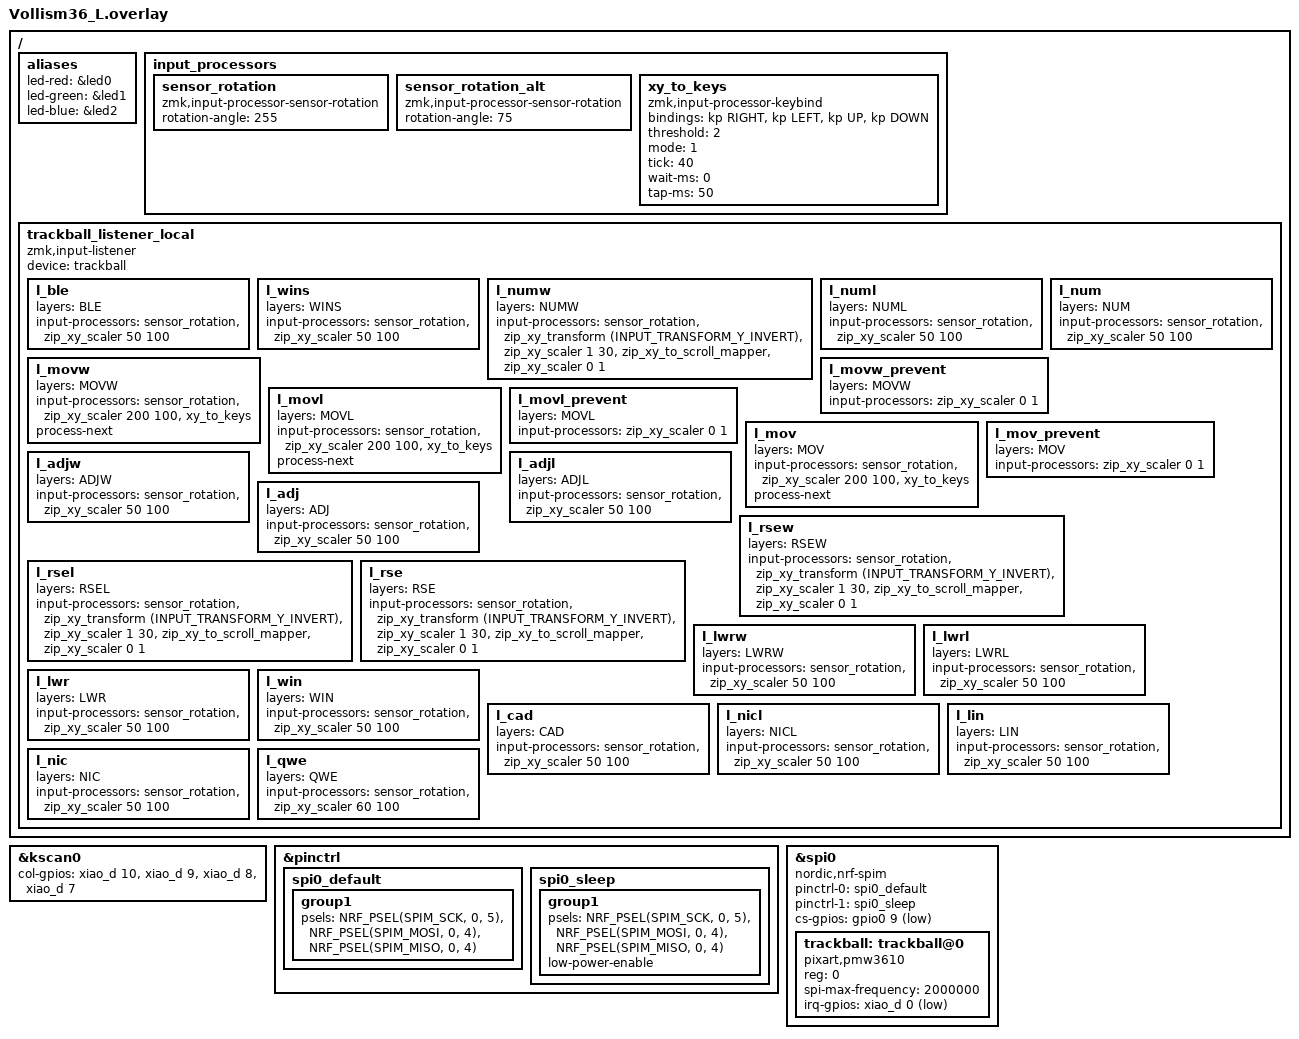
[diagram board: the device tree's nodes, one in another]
#include "Vollism36.dtsi"
#include <input/processors.dtsi>
#include <dt-bindings/zmk/input_transform.h>
#include <dt-bindings/zmk/keys.h>
#include <dt-bindings/input/input-event-codes.h>
#include <input/processors/sensor_rotation.dtsi>
#include <input/processors/zmk-input-processor-keybind.dtsi>
// #include <zephyr/dt-bindings/input/input-event-codes.h>
// #include <behaviors/naginata.dtsi>

#define QWE 0
#define NIC 1
#define LIN 2
#define NICL 3
#define CAD 4
#define WIN 5
#define LWR 6
#define LWRL 7
#define LWRW 8
#define RSE 9
#define RSEL 10
#define RSEW 11
#define ADJ 12
#define ADJL 13
#define ADJW 14
#define MOV 15
#define MOVL 16
#define MOVW 17
#define NUM 18
#define NUML 19
#define NUMW 20
#define WINS 21
#define BLE 22

/ {
    /* 既存の定義（input_processorsなど）と同じ階層に追加 */
    aliases {
        led-red = &led0;   /* Xiao BLE の赤色LEDラベル */
        led-green = &led1; /* Xiao BLE の緑色LEDラベル */
        led-blue = &led2;  /* Xiao BLE の青色LEDラベル */
    };
};


&kscan0 {
        col-gpios
            = <&xiao_d 10 GPIO_ACTIVE_HIGH>
            , <&xiao_d 9 GPIO_ACTIVE_HIGH> 
            , <&xiao_d 8 GPIO_ACTIVE_HIGH> 
            , <&xiao_d 7 GPIO_ACTIVE_HIGH>
            ;
};

/ {
    input_processors {
        /* 既存のデフォルト角度（255度） */
        sensor_rotation: sensor_rotation {
            compatible = "zmk,input-processor-sensor-rotation";
            #input-processor-cells = <0>;
            rotation-angle = <255>;
        };
        /* 新設：別のレイヤで使いたい角度（例：75度） */
        sensor_rotation_alt: sensor_rotation_alt {
            compatible = "zmk,input-processor-sensor-rotation";
            #input-processor-cells = <0>;
            rotation-angle = <75>;  /* ここに対象レイヤで使いたい角度を指定 */
        };

        xy_to_keys: xy_to_keys {
            compatible = "zmk,input-processor-keybind";
            #input-processor-cells = <0>;
            bindings = <&kp RIGHT>, <&kp LEFT>, <&kp UP>, <&kp DOWN>;
            threshold = <2>; // 方向キーが勝手に入る場合はしきい値を少し上げる
            mode = <1>;
            tick = <40>; // ティック間隔
			wait-ms = <0>; // 待機時間
			tap-ms = <50>; // タップ時間
        };
    };

    trackball_listener_local {
        compatible = "zmk,input-listener";
        device = <&trackball>;

        /* ==========================================================
        Layer 22: BLE (通常マウス)
        ========================================================== */
        l_ble {
            layers = <BLE>;
            input-processors = <&sensor_rotation>
                            , <&zip_xy_scaler 50 100>; // スケーリング（50/100）
        };

        /* ==========================================================
        Layer 21: WINS (通常マウス)
        ========================================================== */
        l_wins {
            layers = <WINS>;
            input-processors = <&sensor_rotation>
                            , <&zip_xy_scaler 50 100>; // スケーリング（50/100）
        };

        /* ==========================================================
        Layer 20: NUMW (スクロール)
        ========================================================== */
         l_numw {
            layers = <NUMW>;
            input-processors = 
                <&sensor_rotation>,
                <&zip_xy_transform (INPUT_TRANSFORM_Y_INVERT)>,
                <&zip_xy_scaler 1 30>,
                <&zip_xy_to_scroll_mapper>,
                <&zip_xy_scaler 0 1>; 
        };

        /* ==========================================================
        Layer 19: NUML (通常マウス)
        ========================================================== */
        l_numl {
            layers = <NUML>;
            input-processors = <&sensor_rotation>
                            , <&zip_xy_scaler 50 100>; // スケーリング（50/100）
        };

        /* ==========================================================
        Layer 18: NUM (通常マウス)
        ========================================================== */
        l_num {
            layers = <NUM>;
            input-processors = <&sensor_rotation>
                            , <&zip_xy_scaler 50 100>; // スケーリング（50/100）
        };

        /* ==========================================================
        Layer 17: MOVW (方向キー変換)
        ========================================================== */
        l_movw {
            layers = <MOVW>; 
            input-processors = 
                <&sensor_rotation>, 
                <&zip_xy_scaler 200 100>, 
                <&xy_to_keys>;
            process-next;
        };

        l_movw_prevent {
            layers = <MOVW>;
            input-processors = <&zip_xy_scaler 0 1>;
        };

        /* ==========================================================
        Layer 16: MOVL (方向キー変換)
        ========================================================== */
        l_movl {
            layers = <MOVL>; 
            input-processors = 
                <&sensor_rotation>, 
                <&zip_xy_scaler 200 100>, 
                <&xy_to_keys>;
            process-next;
        };

        l_movl_prevent {
            layers = <MOVL>;
            input-processors = <&zip_xy_scaler 0 1>;
        };

        /* ==========================================================
        Layer 15: MOV (方向キー変換)
        ========================================================== */
        l_mov {
            layers = <MOV>; 
            input-processors = 
                <&sensor_rotation>, 
                <&zip_xy_scaler 200 100>, 
                <&xy_to_keys>;
            process-next;
        };

        l_mov_prevent {
            layers = <MOV>;
            input-processors = <&zip_xy_scaler 0 1>;
        };

        /* ==========================================================
        Layer 14: ADJW (通常マウス)
        ========================================================== */
        l_adjw {
            layers = <ADJW>;
            input-processors = <&sensor_rotation>
                            , <&zip_xy_scaler 50 100>; // スケーリング（50/100）
        };

        /* ==========================================================
        Layer 13: ADJL (通常マウス)
        ========================================================== */
        l_adjl {
            layers = <ADJL>;
            input-processors = <&sensor_rotation>
                            , <&zip_xy_scaler 50 100>; // スケーリング（50/100）
        };

        /* ==========================================================
        Layer 12: ADJ (通常マウス)
        ========================================================== */
        l_adj {
            layers = <ADJ>;
            input-processors = <&sensor_rotation>
                            , <&zip_xy_scaler 50 100>; // スケーリング（50/100）
        };

        /* ==========================================================
        Layer 11: RSEW (スクロール)
        ========================================================== */
        l_rsew {
            layers = <RSEW>;
            input-processors = 
                <&sensor_rotation>,
                <&zip_xy_transform (INPUT_TRANSFORM_Y_INVERT)>,
                <&zip_xy_scaler 1 30>,
                <&zip_xy_to_scroll_mapper>,
                <&zip_xy_scaler 0 1>; 
        };

        /* ==========================================================
        Layer 10: RSEL (スクロール)
        ========================================================== */
        l_rsel {
            layers = <RSEL>;
            input-processors = 
                <&sensor_rotation>,
                <&zip_xy_transform (INPUT_TRANSFORM_Y_INVERT)>,
                <&zip_xy_scaler 1 30>,
                <&zip_xy_to_scroll_mapper>,
                <&zip_xy_scaler 0 1>; 
        };

        /* ==========================================================
        Layer 9: RSE (スクロール)
        ========================================================== */
        l_rse {
            layers = <RSE>;
            input-processors = 
                <&sensor_rotation>,
                <&zip_xy_transform (INPUT_TRANSFORM_Y_INVERT)>,
                <&zip_xy_scaler 1 30>,
                <&zip_xy_to_scroll_mapper>,
                <&zip_xy_scaler 0 1>; 
        };

        /* ==========================================================
        Layer 8: LWRW (通常マウス)
        ========================================================== */
        l_lwrw {
            layers = <LWRW>;
            input-processors = <&sensor_rotation>
                            , <&zip_xy_scaler 50 100>; // スケーリング（50/100）
        };

        /* ==========================================================
        Layer 7: LWRL (通常マウス)
        ========================================================== */
        l_lwrl {
            layers = <LWRL>;
            input-processors = <&sensor_rotation>
                            , <&zip_xy_scaler 50 100>; // スケーリング（50/100）
        };

        /* ==========================================================
        Layer 6: LWR (通常マウス)
        ========================================================== */
        l_lwr {
            layers = <LWR>;
            input-processors = <&sensor_rotation>
                            , <&zip_xy_scaler 50 100>; // スケーリング（50/100）
        };

        /* ==========================================================
        Layer 5: WIN (通常マウス)
        ========================================================== */
        l_win {
            layers = <WIN>;
            input-processors = <&sensor_rotation>
                            , <&zip_xy_scaler 50 100>; // スケーリング（50/100）
        };

        /* ==========================================================
        Layer 4: CAD (通常マウス)
        ========================================================== */
        l_cad {
            layers = <CAD>;
            input-processors = <&sensor_rotation>
                            , <&zip_xy_scaler 50 100>; // スケーリング（50/100）
        };

        /* ==========================================================
        Layer 3: NICL (通常マウス)
        ========================================================== */
        l_nicl {
            layers = <NICL>;
            input-processors = <&sensor_rotation>
                            , <&zip_xy_scaler 50 100>; // スケーリング（50/100）
        };

        // /* ==========================================================
        // Layer 4: NGNL (通常マウス)
        // ========================================================== */
        // l_ngnl {
        //     layers = <NGNL>;
        //     input-processors = <&sensor_rotation>
        //                     , <&zip_xy_scaler 50 100>; // スケーリング（50/100）
        // };

        /* ==========================================================
        Layer 2: LIN (通常マウス)
        ========================================================== */
        l_lin {
            layers = <LIN>;
            input-processors = <&sensor_rotation>
                            , <&zip_xy_scaler 50 100>; // スケーリング（50/100）
        };

        /* ==========================================================
        Layer 1: NIC (通常マウス)
        ========================================================== */
        l_nic {
            layers = <NIC>;
            input-processors = <&sensor_rotation>
                            , <&zip_xy_scaler 50 100>; // スケーリング（50/100）
        };

        // /* ==========================================================
        // Layer 1: NGN (通常マウス)
        // ========================================================== */
        // l_ngn {
        //     layers = <NGN>;
        //     input-processors = <&sensor_rotation>
        //                     , <&zip_xy_scaler 50 100>; // スケーリング（50/100）
        // };

        /* ==========================================================
        Layer 0: QWE (通常マウス)
        ========================================================== */
        l_qwe {
            layers = <QWE>;
            input-processors = <&sensor_rotation>
                            , <&zip_xy_scaler 60 100>; // スケーリング（60/100）
        };
    };
};

&pinctrl {
    spi0_default: spi0_default {
        group1 {
            psels = <NRF_PSEL(SPIM_SCK, 0, 5)>,
                    <NRF_PSEL(SPIM_MOSI, 0, 4)>,
                    <NRF_PSEL(SPIM_MISO, 0, 4)>;
        };
    };

    spi0_sleep: spi0_sleep {
        group1 {
            psels = <NRF_PSEL(SPIM_SCK, 0, 5)>,
                    <NRF_PSEL(SPIM_MOSI, 0, 4)>,
                    <NRF_PSEL(SPIM_MISO, 0, 4)>;
            low-power-enable;
        };
    };
};

&spi0 {
    status = "okay";
    compatible = "nordic,nrf-spim";
    pinctrl-0 = <&spi0_default>;
    pinctrl-1 = <&spi0_sleep>;
    pinctrl-names = "default", "sleep";
    cs-gpios = <&gpio0 9 GPIO_ACTIVE_LOW>;

    trackball: trackball@0 {
        status = "okay";
        compatible = "pixart,pmw3610";
        reg = <0>;
        // evt-type = <INPUT_EV_REL>; // あるいは <INPUT_EV_ABS>
        spi-max-frequency = <2000000>;
        irq-gpios = <&xiao_d 0 (GPIO_ACTIVE_LOW | GPIO_PULL_UP)>;
        // cpi = <600>;
        // evt-type = <INPUT_EV_REL>;
        // x-input-code = <INPUT_REL_X>;
        // y-input-code = <INPUT_REL_Y>;
    };
};
